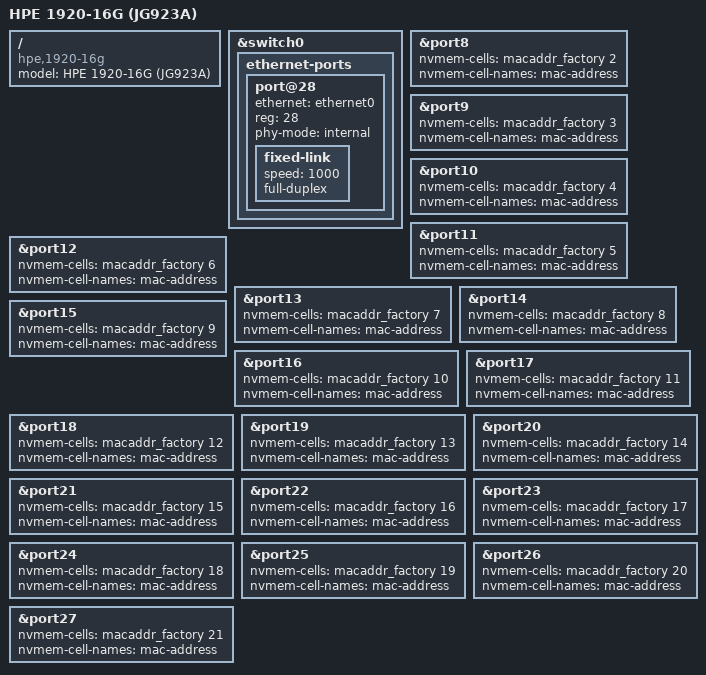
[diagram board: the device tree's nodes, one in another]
// SPDX-License-Identifier: GPL-2.0-or-later OR MIT

#include "rtl8382_hpe_1920.dtsi"

/ {
	compatible = "hpe,1920-16g", "realtek,rtl838x-soc";
	model = "HPE 1920-16G (JG923A)";
};

&switch0 {
	ethernet-ports {
		#address-cells = <1>;
		#size-cells = <0>;

		SWITCH_PORT(8, 1, internal)
		SWITCH_PORT(9, 2, internal)
		SWITCH_PORT(10, 3, internal)
		SWITCH_PORT(11, 4, internal)
		SWITCH_PORT(12, 5, internal)
		SWITCH_PORT(13, 6, internal)
		SWITCH_PORT(14, 7, internal)
		SWITCH_PORT(15, 8, internal)

		SWITCH_PORT_SDS(16, 9, 2, 0, qsgmii)
		SWITCH_PORT_SDS(17, 10, 2, 1, qsgmii)
		SWITCH_PORT_SDS(18, 11, 2, 2, qsgmii)
		SWITCH_PORT_SDS(19, 12, 2, 3, qsgmii)
		SWITCH_PORT_SDS(20, 13, 3, 0, qsgmii)
		SWITCH_PORT_SDS(21, 14, 3, 1, qsgmii)
		SWITCH_PORT_SDS(22, 15, 3, 2, qsgmii)
		SWITCH_PORT_SDS(23, 16, 3, 3, qsgmii)

		SWITCH_PORT_SDS(24, 17, 4, 0, qsgmii)
		SWITCH_PORT_SDS(25, 18, 4, 1, qsgmii)
		SWITCH_PORT_SDS(26, 19, 4, 2, qsgmii)
		SWITCH_PORT_SDS(27, 20, 4, 3, qsgmii)

		port@28 {
			ethernet = <&ethernet0>;
			reg = <28>;
			phy-mode = "internal";
			fixed-link {
				speed = <1000>;
				full-duplex;
			};
		};
	};
};

&port8 {
	nvmem-cells = <&macaddr_factory 2>;
	nvmem-cell-names = "mac-address";
};

&port9 {
	nvmem-cells = <&macaddr_factory 3>;
	nvmem-cell-names = "mac-address";
};

&port10 {
	nvmem-cells = <&macaddr_factory 4>;
	nvmem-cell-names = "mac-address";
};

&port11 {
	nvmem-cells = <&macaddr_factory 5>;
	nvmem-cell-names = "mac-address";
};

&port12 {
	nvmem-cells = <&macaddr_factory 6>;
	nvmem-cell-names = "mac-address";
};

&port13 {
	nvmem-cells = <&macaddr_factory 7>;
	nvmem-cell-names = "mac-address";
};

&port14 {
	nvmem-cells = <&macaddr_factory 8>;
	nvmem-cell-names = "mac-address";
};

&port15 {
	nvmem-cells = <&macaddr_factory 9>;
	nvmem-cell-names = "mac-address";
};

&port16 {
	nvmem-cells = <&macaddr_factory 10>;
	nvmem-cell-names = "mac-address";
};

&port17 {
	nvmem-cells = <&macaddr_factory 11>;
	nvmem-cell-names = "mac-address";
};

&port18 {
	nvmem-cells = <&macaddr_factory 12>;
	nvmem-cell-names = "mac-address";
};

&port19 {
	nvmem-cells = <&macaddr_factory 13>;
	nvmem-cell-names = "mac-address";
};

&port20 {
	nvmem-cells = <&macaddr_factory 14>;
	nvmem-cell-names = "mac-address";
};

&port21 {
	nvmem-cells = <&macaddr_factory 15>;
	nvmem-cell-names = "mac-address";
};

&port22 {
	nvmem-cells = <&macaddr_factory 16>;
	nvmem-cell-names = "mac-address";
};

&port23 {
	nvmem-cells = <&macaddr_factory 17>;
	nvmem-cell-names = "mac-address";
};

&port24 {
	nvmem-cells = <&macaddr_factory 18>;
	nvmem-cell-names = "mac-address";
};

&port25 {
	nvmem-cells = <&macaddr_factory 19>;
	nvmem-cell-names = "mac-address";
};

&port26 {
	nvmem-cells = <&macaddr_factory 20>;
	nvmem-cell-names = "mac-address";
};

&port27 {
	nvmem-cells = <&macaddr_factory 21>;
	nvmem-cell-names = "mac-address";
};
